# ESP32-S2 register map
Vendor: ESPRESSIF SYSTEMS (SHANGHAI) CO., LTD.; Series: ESP32 S-Series; File version: 20
CPU: Xtensa LX7 r0p0, little endian, no MPU, no FPU, 0 interrupt priority bits
Address unit: 32 bits
Registers are 32-bit, read-write, reset 0x0 unless marked. A register's access mark holds for its fields unless they carry their own. Offsets are from the block's base; [hi:lo] are bit positions.

## COPY_DMA — Copy DMA Controller
Base 0x3F4C3000
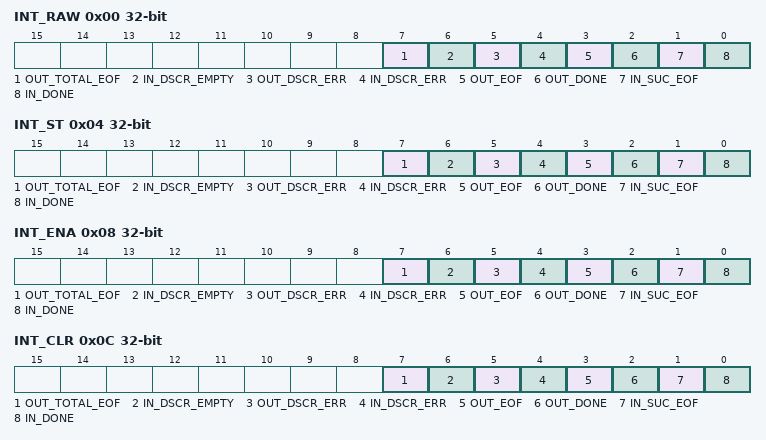
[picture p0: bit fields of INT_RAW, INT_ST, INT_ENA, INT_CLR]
0x00 INT_RAW ro — Raw interrupt status
  [7] OUT_TOTAL_EOF — Triggered when data corresponding to all transmit descriptors and the last descriptor with valid EOF is transmitted out.
  [6] IN_DSCR_EMPTY — Triggered when receiving data is completed and no more receive descriptor.
  [5] OUT_DSCR_ERR — Triggered when detecting transmit descriptor error, including owner error, the second and third word error of transmit descriptor.
  [4] IN_DSCR_ERR — Triggered when detecting receive descriptor error, including owner error, the second and third word error of receive descriptor.
  [3] OUT_EOF — Triggered when the last data with EOF flag has been pushed into TX FIFO.
  [2] OUT_DONE — Triggered when all data indicated by one transmit descriptor has been pushed into TX FIFO.
  [1] IN_SUC_EOF — Triggered when the last data of one frame is received.
  [0] IN_DONE — Triggered when the last data of frame is received or the receive buffer is full indicated by receive descriptor.
0x04 INT_ST ro — Masked interrupt status
  [7] OUT_TOTAL_EOF — This is the masked interrupt bit for OUT_TOTAL_EOF interrupt when OUT_TOTAL_EOF is enabled.
  [6] IN_DSCR_EMPTY — This is the masked interrupt bit for IN_DSCR_EMPTY interrupt when IN_DSCR_EMPTY is enabled.
  [5] OUT_DSCR_ERR — This is the masked interrupt bit for OUT_DSCR_ERR interrupt when OUT_DSCR_ERR is enabled.
  [4] IN_DSCR_ERR — This is the masked interrupt bit for IN_DSCR_ERR interrupt when IN_DSCR_ERR is enabled.
  [3] OUT_EOF — This is the masked interrupt bit for OUT_EOF interrupt when OUT_EOF is enabled.
  [2] OUT_DONE — This is the masked interrupt bit for OUT_DONE interrupt when OUT_DONE is enabled.
  [1] IN_SUC_EOF — This is the masked interrupt bit for IN_SUC_EOF interrupt when IN_SUC_EOF is enabled.
  [0] IN_DONE — This is the masked interrupt bit for IN_DONE interrupt when IN_DONE is enabled.
0x08 INT_ENA — Interrupt enable bits
  [7] OUT_TOTAL_EOF — This is the interrupt enable bit for OUT_TOTAL_EOF interrupt.
  [6] IN_DSCR_EMPTY — This is the interrupt enable bit for IN_DSCR_EMPTY interrupt.
  [5] OUT_DSCR_ERR — This is the interrupt enable bit for OUT_DSCR_ERR interrupt.
  [4] IN_DSCR_ERR — This is the interrupt enable bit for IN_DSCR_ERR interrupt.
  [3] OUT_EOF — This is the interrupt enable bit for OUT_EOF interrupt.
  [2] OUT_DONE — This is the interrupt enable bit for OUT_DONE interrupt.
  [1] IN_SUC_EOF — This is the interrupt enable bit for IN_SUC_EOF interrupt.
  [0] IN_DONE — This is the interrupt enable bit for IN_DONE interrupt.
0x0C INT_CLR wo — Interrupt clear bits
  [7] OUT_TOTAL_EOF write-1-clears — Set this bit to clear OUT_TOTAL_EOF interrupt.
  [6] IN_DSCR_EMPTY write-1-clears — Set this bit to clear IN_DSCR_EMPTY interrupt.
  [5] OUT_DSCR_ERR write-1-clears — Set this bit to clear OUT_DSCR_ERR interrupt.
  [4] IN_DSCR_ERR write-1-clears — Set this bit to clear IN_DSCR_ERR interrupt.
  [3] OUT_EOF write-1-clears — Set this bit to clear OUT_EOF interrupt.
  [2] OUT_DONE write-1-clears — Set this bit to clear OUT_DONE interrupt.
  [1] IN_SUC_EOF write-1-clears — Set this bit to clear IN_SUC_EOF interrupt.
  [0] IN_DONE write-1-clears — Set this bit to clear IN_DONE interrupt.
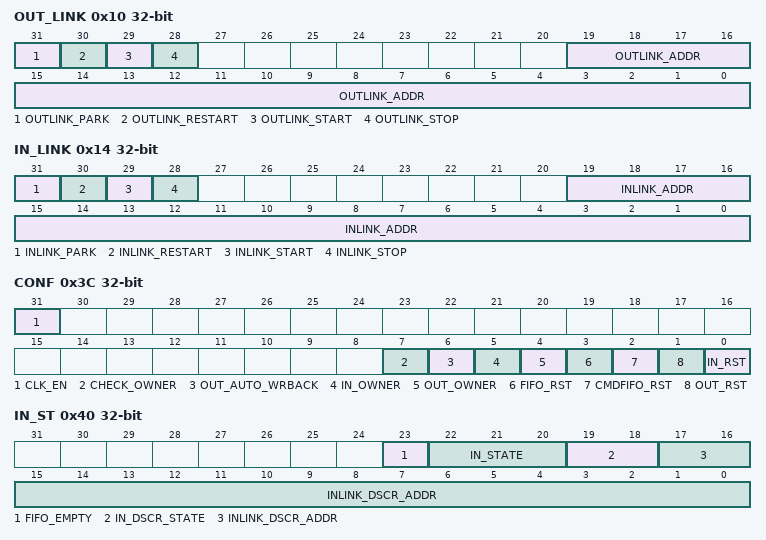
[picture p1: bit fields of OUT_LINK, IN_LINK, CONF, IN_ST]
0x10 OUT_LINK — Link descriptor address and control
  [31] OUTLINK_PARK — 1: the transmit descriptor’s FSM is in idle state. 0: the transmit descriptor’s FSM is working.
    0=WORKING (The transmit descriptor’s FSM is working.); 1=IDLE (The transmit descriptor’s FSM is in idle state)
  [30] OUTLINK_RESTART — Set this bit to restart the transmit descriptor from the last address.
  [29] OUTLINK_START — Set this bit to start a new transmit descriptor.
  [28] OUTLINK_STOP — Set this bit to stop DMA from reading transmit descriptors after finishing the current data transaction.
  [19:0] OUTLINK_ADDR — This register is used to specify the least significant 20 bits of the first transmit descriptor’s address.
0x14 IN_LINK — Link descriptor address and control
  [31] INLINK_PARK — 1: the receive descriptor’s FSM is in idle state. 0: the receive descriptor’s FSM is working.
    0=WORKING (The receive descriptor’s FSM is working.); 1=IDLE (The receive descriptor’s FSM is in idle state)
  [30] INLINK_RESTART — Set this bit to restart new receive descriptors.
  [29] INLINK_START — Set this bit to enable DMA to read receive descriptor.
  [28] INLINK_STOP — Set this bit to stop DMA from reading receive descriptors after finishing the current data transaction.
  [19:0] INLINK_ADDR — This register is used to specify the least significant 20 bits of the first receive descriptor’s address.
0x18 OUT_EOF_DES_ADDR ro — Transmit descriptor address when EOF occurs
  [31:0] OUT_EOF_DES_ADDR — This register stores the address of the transmit descriptor when the EOF bit in this descriptor is 1.
0x1C IN_EOF_DES_ADDR ro — Receive descriptor address when EOF occurs
  [31:0] IN_SUC_EOF_DES_ADDR — This register stores the address of the receive descriptor when received successful EOF.
0x20 OUT_EOF_BFR_DES_ADDR ro — Transmit descriptor address before the last transmit descriptor
  [31:0] OUT_EOF_BFR_DES_ADDR — This register stores the address of the transmit descriptor before the last transmit descriptor.
0x24 INLINK_DSCR ro — Address of current receive descriptor
  [31:0] INLINK_DSCR — The address of the current receive descriptor x.
0x28 INLINK_DSCR_BF0 ro — Address of last receive descriptor
  [31:0] INLINK_DSCR_BF0 — The address of the last receive descriptor x-1.
0x30 OUTLINK_DSCR ro — Address of current transmit descriptor
  [31:0] OUTLINK_DSCR — The address of the current transmit descriptor y.
0x34 OUTLINK_DSCR_BF0 ro — Address of last transmit descriptor
  [31:0] OUTLINK_DSCR_BF0 — The address of the last transmit descriptor y-1.
0x3C CONF — Copy DMA configuration register
  [31] CLK_EN — 1’b1: Force clock on for register. 1’b0: Support clock only when application writes registers.
    0=ON_WRITE (Support clock only when application writes registers); 1=FORCE (Force clock on for register)
  [7] CHECK_OWNER — Set this bit to enable owner bit check in descriptor.
  [6] OUT_AUTO_WRBACK — This bit is used to write back out descriptor when hardware has already used this descriptor.
  [5] IN_OWNER — This is used to configure the owner bit in receive descriptor.
  [4] OUT_OWNER — This is used to configure the owner bit in transmit descriptor. This is effective only when you set OUT_AUTO_WRBACK.
  [3] FIFO_RST — Set this bit to reset data in RX FIFO.
  [2] CMDFIFO_RST — Set this bit to reset in_cmd FIFO and out_cmd FIFO.
  [1] OUT_RST — Set this bit to reset out DMA FSM.
  [0] IN_RST — Set this bit to reset in DMA FSM.
0x40 IN_ST ro — Status register of receiving data
  [23] FIFO_EMPTY — Copy DMA FIFO empty signal.
  [22:20] IN_STATE — Reserved
  [19:18] IN_DSCR_STATE — Reserved
  [17:0] INLINK_DSCR_ADDR — This register stores the current receive descriptor’s address.
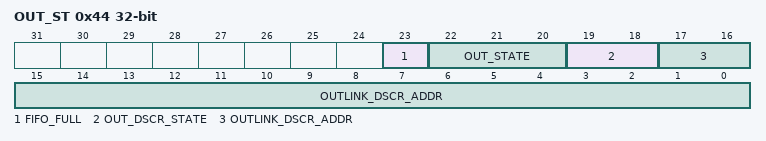
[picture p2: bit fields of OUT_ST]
0x44 OUT_ST ro — Status register of transmitting data
  [23] FIFO_FULL — Copy DMA FIFO full signal.
  [22:20] OUT_STATE — Reserved
  [19:18] OUT_DSCR_STATE — Reserved
  [17:0] OUTLINK_DSCR_ADDR — This register stores the current transmit descriptor’s address.
0xFC DATE — Copy DMA version control register
